# 3065HRPIRZ register map
File version: 1.0
Registers are 32-bit, access per field, reset 0x0 unless marked. A register's access mark holds for its fields unless they carry their own. Offsets are from the block's base; [hi:lo] are bit positions.

## IOCMG_CORE — IOCMG_CORE peripheral interface
Base 0x147F0000
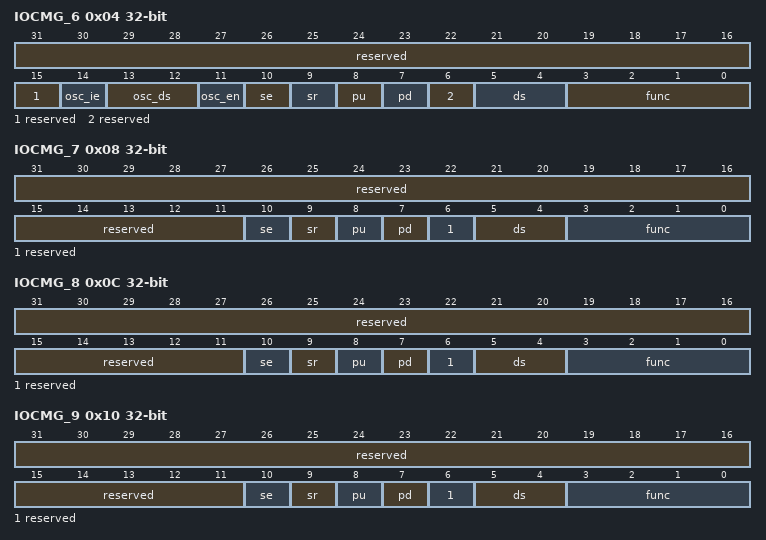
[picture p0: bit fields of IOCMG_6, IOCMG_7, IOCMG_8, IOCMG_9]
0x04 IOCMG_6 — XTAL_OUT 管脚配置寄存器。
  [31:15] reserved ro — 保留。
  [14] osc_ie rw — XOUT/XIN管脚晶振功能时钟输出使能控制。 0x0：关闭； 0x1：打开。
  [13:12] osc_ds rw — XOUT/XIN 管脚晶振功能驱动能力选择（档位越大，驱动能力越大） 。 00：档位1； 01：档位2； 10：档位3； 11：档位4。
  [11] osc_en rw — XOUT/XIN管脚晶振功能使能控制。 0x0：GPIO功能； 0x1：OSC功能。
  [10] se rw — 管脚施密特输入控制。 0x0：关闭； 0x1：打开。
  [9] sr rw — 管脚电平转换速率控制。 0x0：快沿输出； 0x1：慢沿输出。
  [8] pu rw — 管脚上拉控制。 0x0：关闭； 0x1：打开。
  [7] pd rw — 管脚下拉控制。 0x0：关闭； 0x1：打开。
  [6] reserved ro — 保留。
  [5:4] ds rw — 管脚驱动能力选择（档位越大，驱动能力越大）。 00：档位4； 01：档位3； 10：档位2； 11：档位1。
  [3:0] func rw — 功能选择。 0x0: GPIO0_3； 0x2: GPT0_PWM； 0x4: UART0_TXD； 0x8: XTAL_OUT； 其它: 保留。
0x08 IOCMG_7 — XTAL_IN 管脚配置寄存器。
  [31:11] reserved ro — 保留。
  [10] se rw — 管脚施密特输入控制。 0x0：关闭； 0x1：打开。
  [9] sr rw — 管脚电平转换速率控制。 0x0：快沿输出； 0x1：慢沿输出。
  [8] pu rw — 管脚上拉控制。 0x0：关闭； 0x1：打开。
  [7] pd rw — 管脚下拉控制。 0x0：关闭； 0x1：打开。
  [6] reserved ro — 保留。
  [5:4] ds rw — 管脚驱动能力选择（档位越大，驱动能力越大）。 00：档位4； 01：档位3； 10：档位2； 11：档位1。
  [3:0] func rw — 功能选择。 0x0: GPIO0_4； 0x4: UART0_RXD； 0x8: XTAL_IN； 其它: 保留。
0x0C IOCMG_8 — GPT0 管脚配置寄存器。
  [31:11] reserved ro — 保留。
  [10] se rw — 管脚施密特输入控制。 0x0：关闭； 0x1：打开。
  [9] sr rw — 管脚电平转换速率控制。 0x0：快沿输出； 0x1：慢沿输出。
  [8] pu rw — 管脚上拉控制。 0x0：关闭； 0x1：打开。
  [7] pd rw — 管脚下拉控制。 0x0：关闭； 0x1：打开。
  [6] reserved ro — 保留。
  [5:4] ds rw — 管脚驱动能力选择（档位越大，驱动能力越大）。 00：档位4； 01：档位3； 10：档位2； 11：档位1。
  [3:0] func rw — 功能选择。 0x0: GPIO0_5； 0x1: GPT0_PWM； 0x2: APT_EVTMP5； 0x3: CAPM1_SRC0； 其它: 保留。
0x10 IOCMG_9 — GPIO0_6 管脚配置寄存器。
  [31:11] reserved ro — 保留。
  [10] se rw — 管脚施密特输入控制。 0x0：关闭； 0x1：打开。
  [9] sr rw — 管脚电平转换速率控制。 0x0：快沿输出； 0x1：慢沿输出。
  [8] pu rw — 管脚上拉控制。 0x0：关闭； 0x1：打开。
  [7] pd rw — 管脚下拉控制。 0x0：关闭； 0x1：打开。
  [6] reserved ro — 保留。
  [5:4] ds rw — 管脚驱动能力选择（档位越大，驱动能力越大）。 00：档位4； 01：档位3； 10：档位2； 11：档位1。
  [3:0] func rw — 功能选择。 0x0: GPIO0_6； 0x1: CAN_RX； 0x2: APT_EVTIO5； 其它: 保留。
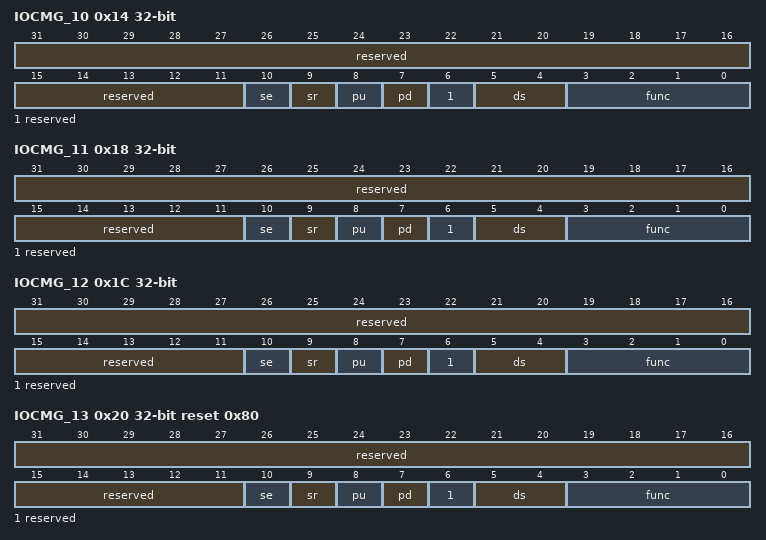
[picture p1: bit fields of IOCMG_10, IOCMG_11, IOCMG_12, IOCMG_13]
0x14 IOCMG_10 — GPIO0_7 管脚配置寄存器。
  [31:11] reserved ro — 保留。
  [10] se rw — 管脚施密特输入控制。 0x0：关闭； 0x1：打开。
  [9] sr rw — 管脚电平转换速率控制。 0x0：快沿输出； 0x1：慢沿输出。
  [8] pu rw — 管脚上拉控制。 0x0：关闭； 0x1：打开。
  [7] pd rw — 管脚下拉控制。 0x0：关闭； 0x1：打开。
  [6] reserved ro — 保留。
  [5:4] ds rw — 管脚驱动能力选择（档位越大，驱动能力越大）。 00：档位4； 01：档位3； 10：档位2； 11：档位1。
  [3:0] func rw — 功能选择。 0x0: GPIO0_7； 0x1: CAN_TX； 其它: 保留。
0x18 IOCMG_11 — QDM_A 管脚配置寄存器。
  [31:11] reserved ro — 保留。
  [10] se rw — 管脚施密特输入控制。 0x0：关闭； 0x1：打开。
  [9] sr rw — 管脚电平转换速率控制。 0x0：快沿输出； 0x1：慢沿输出。
  [8] pu rw — 管脚上拉控制。 0x0：关闭； 0x1：打开。
  [7] pd rw — 管脚下拉控制。 0x0：关闭； 0x1：打开。
  [6] reserved ro — 保留。
  [5:4] ds rw — 管脚驱动能力选择（档位越大，驱动能力越大）。 00：档位4； 01：档位3； 10：档位2； 11：档位1。
  [3:0] func rw — 功能选择。 0x0: GPIO1_0； 0x1: QDM_A； 其它: 保留。
0x1C IOCMG_12 — QDM_B 管脚配置寄存器。
  [31:11] reserved ro — 保留。
  [10] se rw — 管脚施密特输入控制。 0x0：关闭； 0x1：打开。
  [9] sr rw — 管脚电平转换速率控制。 0x0：快沿输出； 0x1：慢沿输出。
  [8] pu rw — 管脚上拉控制。 0x0：关闭； 0x1：打开。
  [7] pd rw — 管脚下拉控制。 0x0：关闭； 0x1：打开。
  [6] reserved ro — 保留。
  [5:4] ds rw — 管脚驱动能力选择（档位越大，驱动能力越大）。 00：档位4； 01：档位3； 10：档位2； 11：档位1。
  [3:0] func rw — 功能选择。 0x0: GPIO1_1； 0x1: QDM_B； 其它: 保留。
0x20 IOCMG_13 reset 0x80 — BOOT/GPIO1_2 管脚配置寄存器。
  [31:11] reserved ro — 保留。
  [10] se rw — 管脚施密特输入控制。 0x0：关闭； 0x1：打开。
  [9] sr rw — 管脚电平转换速率控制。 0x0：快沿输出； 0x1：慢沿输出。
  [8] pu rw — 管脚上拉控制。 0x0：关闭； 0x1：打开。
  [7] pd rw — 管脚下拉控制。 0x0：关闭； 0x1：打开。
  [6] reserved ro — 保留。
  [5:4] ds rw — 管脚驱动能力选择（档位越大，驱动能力越大）。 00：档位4； 01：档位3； 10：档位2； 11：档位1。
  [3:0] func rw — 功能选择。 0x0: GPIO1_2； 0x1: UPDATE_MODE； 0x2: TEST_CLK； 0x4: UART1_RTSN； 其它: 保留。
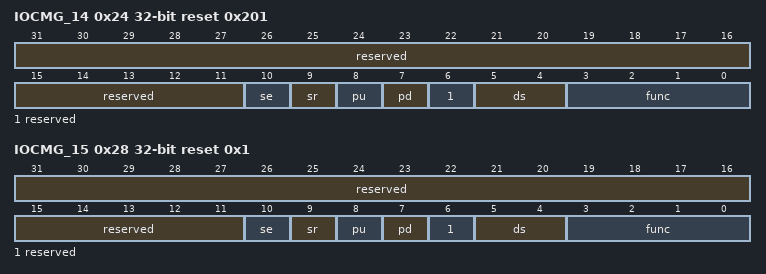
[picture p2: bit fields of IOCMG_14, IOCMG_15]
0x24 IOCMG_14 reset 0x201 — TDO/GPT1/UART1_RX 管脚配置寄存器。
  [31:11] reserved ro — 保留。
  [10] se rw — 管脚施密特输入控制。 0x0：关闭； 0x1：打开。
  [9] sr rw — 管脚电平转换速率控制。 0x0：快沿输出； 0x1：慢沿输出。
  [8] pu rw — 管脚上拉控制。 0x0：关闭； 0x1：打开。
  [7] pd rw — 管脚下拉控制。 0x0：关闭； 0x1：打开。
  [6] reserved ro — 保留。
  [5:4] ds rw — 管脚驱动能力选择（档位越大，驱动能力越大）。 00：档位4； 01：档位3； 10：档位2； 11：档位1。
  [3:0] func rw — 功能选择。 0x0: GPIO1_3； 0x1: JTAG_TDO； 0x2: GPT1_PWM； 0x3: CAPM2_SRC0； 0x4: UART1_RXD； 0x5: I2C0_SCL； 其它: 保留。
0x28 IOCMG_15 reset 0x1 — TDI/CAPM0/UART1_TX 管脚配置寄存器。
  [31:11] reserved ro — 保留。
  [10] se rw — 管脚施密特输入控制。 0x0：关闭； 0x1：打开。
  [9] sr rw — 管脚电平转换速率控制。 0x0：快沿输出； 0x1：慢沿输出。
  [8] pu rw — 管脚上拉控制。 0x0：关闭； 0x1：打开。
  [7] pd rw — 管脚下拉控制。 0x0：关闭； 0x1：打开。
  [6] reserved ro — 保留。
  [5:4] ds rw — 管脚驱动能力选择（档位越大，驱动能力越大）。 00：档位4； 01：档位3； 10：档位2； 11：档位1。
  [3:0] func rw — 功能选择。 0x0: GPIO1_4； 0x1: JTAG_TDI； 0x3: CAPM0_SRC0； 0x4: UART1_TXD； 0x5: I2C0_SDA； 其它: 保留。
